# STM32F778AIY6 register map
File version: 1.0
Registers are 32-bit, access not given, reset 0x0 unless marked. A register's access mark holds for its fields unless they carry their own. Offsets are from the block's base; [hi:lo] are bit positions; {n}, {i} and the like mark numbered series; 'fields as' and 'values as' point back to an identical list.

## LPTIM1
Base 0x40002400
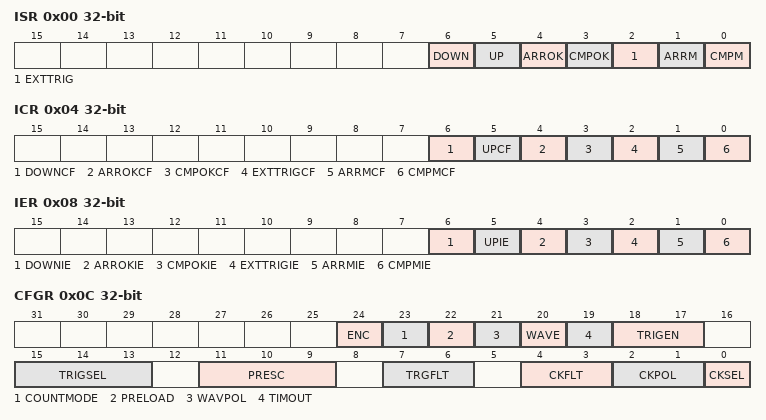
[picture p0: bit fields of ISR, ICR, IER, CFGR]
0x00 ISR
  [6] DOWN, [5] UP, [4] ARROK, [3] CMPOK, [2] EXTTRIG, [1] ARRM, [0] CMPM
0x04 ICR
  [6] DOWNCF, [5] UPCF, [4] ARROKCF, [3] CMPOKCF, [2] EXTTRIGCF, [1] ARRMCF, [0] CMPMCF
0x08 IER
  [6] DOWNIE, [5] UPIE, [4] ARROKIE, [3] CMPOKIE, [2] EXTTRIGIE, [1] ARRMIE, [0] CMPMIE
0x0C CFGR
  [24] ENC, [23] COUNTMODE, [22] PRELOAD, [21] WAVPOL, [20] WAVE, [19] TIMOUT, [18:17] TRIGEN, [15:13] TRIGSEL, [11:9] PRESC, [7:6] TRGFLT, [4:3] CKFLT, [2:1] CKPOL, [0] CKSEL
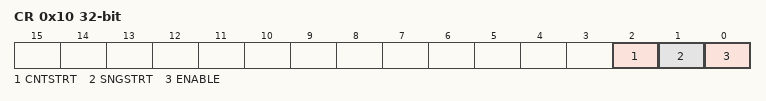
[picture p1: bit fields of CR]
0x10 CR
  [2] CNTSTRT, [1] SNGSTRT, [0] ENABLE
0x14 CMP
  [15:0] CMP
0x18 ARR
  [15:0] ARR
0x1C CNT
  [15:0] CNT

## RTC
Base 0x40002800
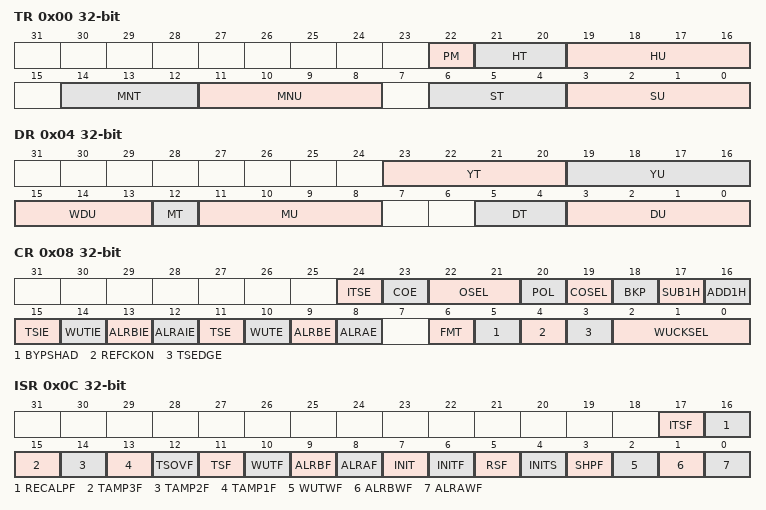
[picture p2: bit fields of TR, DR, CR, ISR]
0x00 TR
  [22] PM, [21:20] HT, [19:16] HU, [14:12] MNT, [11:8] MNU, [6:4] ST, [3:0] SU
0x04 DR
  [23:20] YT, [19:16] YU, [15:13] WDU, [12] MT, [11:8] MU, [5:4] DT, [3:0] DU
0x08 CR
  [24] ITSE, [23] COE, [22:21] OSEL, [20] POL, [19] COSEL, [18] BKP, [17] SUB1H, [16] ADD1H, [15] TSIE, [14] WUTIE, [13] ALRBIE, [12] ALRAIE, [11] TSE, [10] WUTE, [9] ALRBE, [8] ALRAE, [6] FMT, [5] BYPSHAD, [4] REFCKON, [3] TSEDGE, [2:0] WUCKSEL
0x0C ISR
  [17] ITSF, [16] RECALPF, [15] TAMP3F, [14] TAMP2F, [13] TAMP1F, [12] TSOVF, [11] TSF, [10] WUTF, [9] ALRBF, [8] ALRAF, [7] INIT, [6] INITF, [5] RSF, [4] INITS, [3] SHPF, [2] WUTWF, [1] ALRBWF, [0] ALRAWF
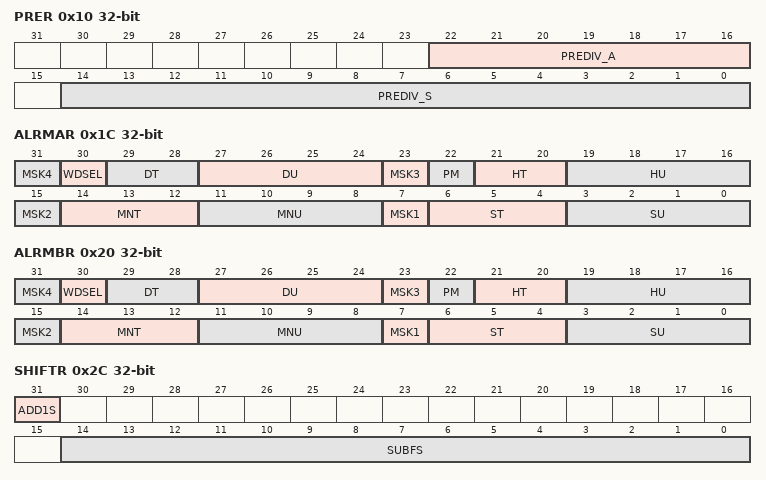
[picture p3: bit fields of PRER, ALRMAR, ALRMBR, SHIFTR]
0x10 PRER
  [22:16] PREDIV_A, [14:0] PREDIV_S
0x14 WUTR
  [15:0] WUT
0x1C ALRMAR
  [8n-1] MSK{n} (n=1..4), [30] WDSEL, [29:28] DT, [27:24] DU, [22] PM, [21:20] HT, [19:16] HU, [14:12] MNT, [11:8] MNU, [6:4] ST, [3:0] SU
0x20 ALRMBR
  fields as ALRMAR
0x24 WPR
  [7:0] KEY
0x28 SSR
  [15:0] SS
0x2C SHIFTR
  [31] ADD1S, [14:0] SUBFS
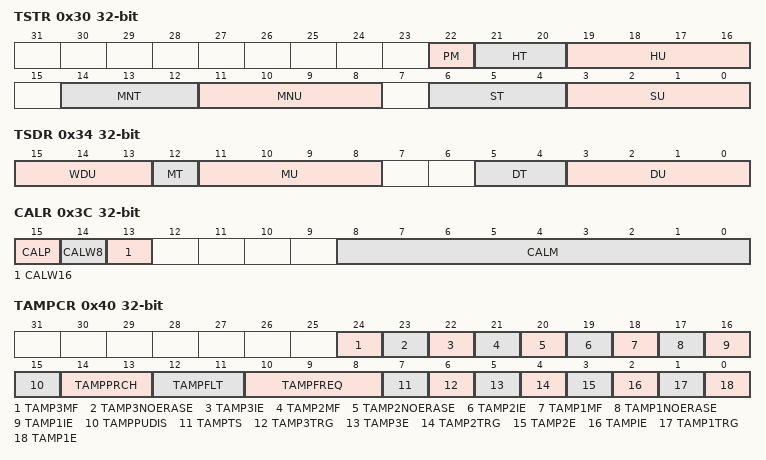
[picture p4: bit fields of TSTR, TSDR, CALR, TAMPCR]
0x30 TSTR
  fields as TR
0x34 TSDR
  [15:13] WDU, [12] MT, [11:8] MU, [5:4] DT, [3:0] DU
0x38 TSSSR
  [15:0] SS
0x3C CALR
  [15] CALP, [14] CALW8, [13] CALW16, [8:0] CALM
0x40 TAMPCR
  [24] TAMP3MF, [23] TAMP3NOERASE, [22] TAMP3IE, [21] TAMP2MF, [20] TAMP2NOERASE, [19] TAMP2IE, [18] TAMP1MF, [17] TAMP1NOERASE, [16] TAMP1IE, [15] TAMPPUDIS, [14:13] TAMPPRCH, [12:11] TAMPFLT, [10:8] TAMPFREQ, [7] TAMPTS, [6] TAMP3TRG, [5] TAMP3E, [4] TAMP2TRG, [3] TAMP2E, [2] TAMPIE, [1] TAMP1TRG, [0] TAMP1E
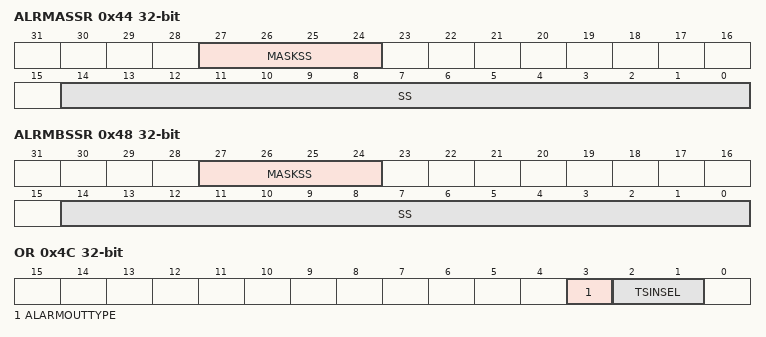
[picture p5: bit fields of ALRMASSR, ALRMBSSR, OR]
0x44 ALRMASSR
  [27:24] MASKSS, [14:0] SS
0x48 ALRMBSSR
  [27:24] MASKSS, [14:0] SS
0x4C OR
  [3] ALARMOUTTYPE, [2:1] TSINSEL
{0x50+4i} BKP{i}R (i=0..31)

## WWDG
Base 0x40002C00
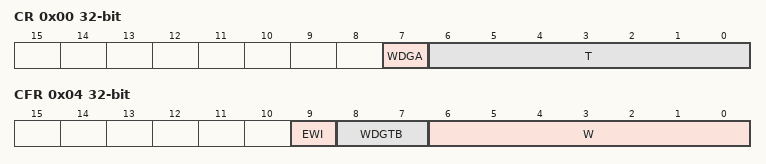
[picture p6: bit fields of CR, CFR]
0x00 CR
  [7] WDGA, [6:0] T
0x04 CFR
  [9] EWI, [8:7] WDGTB, [6:0] W
0x08 SR
  [0] EWIF

## IWDG
Base 0x40003000
0x00 KR
  [15:0] KEY
0x04 PR
  [2:0] PR
0x08 RLR
  [11:0] RL
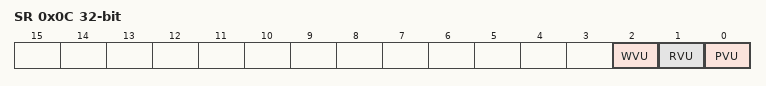
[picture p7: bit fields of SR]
0x0C SR
  [2] WVU, [1] RVU, [0] PVU
0x10 WINR
  [11:0] WIN

## SPI2
Base 0x40003800
Same registers: SPI3 0x40003C00, SPI1 0x40013000, SPI4 0x40013400, SPI5 0x40015000, SPI6 0x40015400
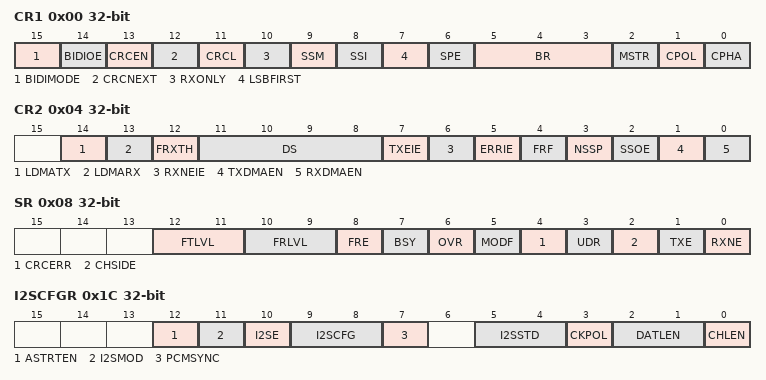
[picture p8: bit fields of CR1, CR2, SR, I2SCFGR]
0x00 CR1
  [15] BIDIMODE, [14] BIDIOE, [13] CRCEN, [12] CRCNEXT, [11] CRCL, [10] RXONLY, [9] SSM, [8] SSI, [7] LSBFIRST, [6] SPE, [5:3] BR, [2] MSTR, [1] CPOL, [0] CPHA
0x04 CR2
  [14] LDMATX, [13] LDMARX, [12] FRXTH, [11:8] DS, [7] TXEIE, [6] RXNEIE, [5] ERRIE, [4] FRF, [3] NSSP, [2] SSOE, [1] TXDMAEN, [0] RXDMAEN
0x08 SR
  [12:11] FTLVL, [10:9] FRLVL, [8] FRE, [7] BSY, [6] OVR, [5] MODF, [4] CRCERR, [3] UDR, [2] CHSIDE, [1] TXE, [0] RXNE
0x0C DR
  [15:0] DR
0x10 CRCPR
  [15:0] CRCPOLY
0x14 RXCRCR
  [15:0] RXCRC
0x18 TXCRCR
  [15:0] TXCRC
0x1C I2SCFGR
  [12] ASTRTEN, [11] I2SMOD, [10] I2SE, [9:8] I2SCFG, [7] PCMSYNC, [5:4] I2SSTD, [3] CKPOL, [2:1] DATLEN, [0] CHLEN
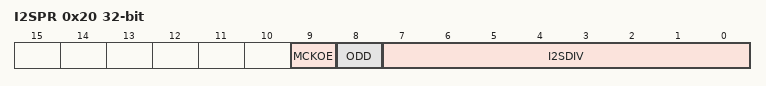
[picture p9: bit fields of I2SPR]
0x20 I2SPR
  [9] MCKOE, [8] ODD, [7:0] I2SDIV

## SPDIFRX
Base 0x40004000
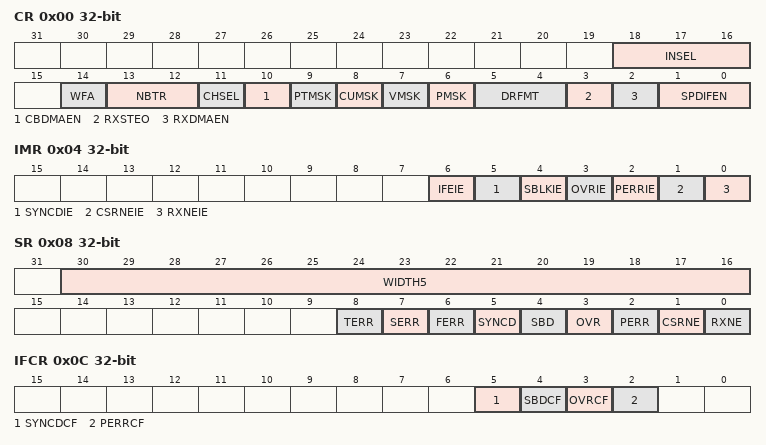
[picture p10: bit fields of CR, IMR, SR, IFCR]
0x00 CR
  [18:16] INSEL, [14] WFA, [13:12] NBTR, [11] CHSEL, [10] CBDMAEN, [9] PTMSK, [8] CUMSK, [7] VMSK, [6] PMSK, [5:4] DRFMT, [3] RXSTEO, [2] RXDMAEN, [1:0] SPDIFEN
0x04 IMR
  [6] IFEIE, [5] SYNCDIE, [4] SBLKIE, [3] OVRIE, [2] PERRIE, [1] CSRNEIE, [0] RXNEIE
0x08 SR
  [30:16] WIDTH5, [8] TERR, [7] SERR, [6] FERR, [5] SYNCD, [4] SBD, [3] OVR, [2] PERR, [1] CSRNE, [0] RXNE
0x0C IFCR
  [5] SYNCDCF, [4] SBDCF, [3] OVRCF, [2] PERRCF
0x10 DR
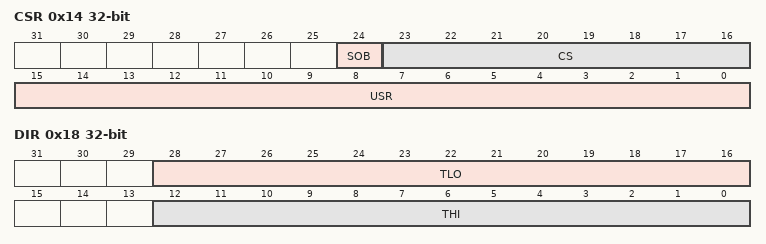
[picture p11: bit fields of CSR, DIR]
0x14 CSR
  [24] SOB, [23:16] CS, [15:0] USR
0x18 DIR
  [28:16] TLO, [12:0] THI
